# L4PER_PRM register map
Vendor: Texas Instruments
Peripheral module from a debugger description file (folder TDA2Px).
Registers are 32-bit, access per field, reset 0x0 unless marked. A register's access mark holds for its fields unless they carry their own. Offsets are as the file gives them; lines under a group give offsets from that group; [hi:lo] are bit positions; {n}, {i} and the like mark numbered series; 'fields as' and 'values as' point back to an identical list; <NAME> marks a mode.

## L4PER_PRM (part 1 of 2)
0x11C RM_L4PER_GPIO8_CONTEXT reset 0x2 — This register contains dedicated GPIO8 context statuses. [warm reset insensitive]
  [1] LOSTCONTEXT_RFF rw — Specify if RFF-based context has been lost due to a previous power transition or other reset source. (set upon assertion of L4PER_RET_RST signal)
    0=MAINTAINED (Context has been maintained); 1=LOST (Context has been lost)
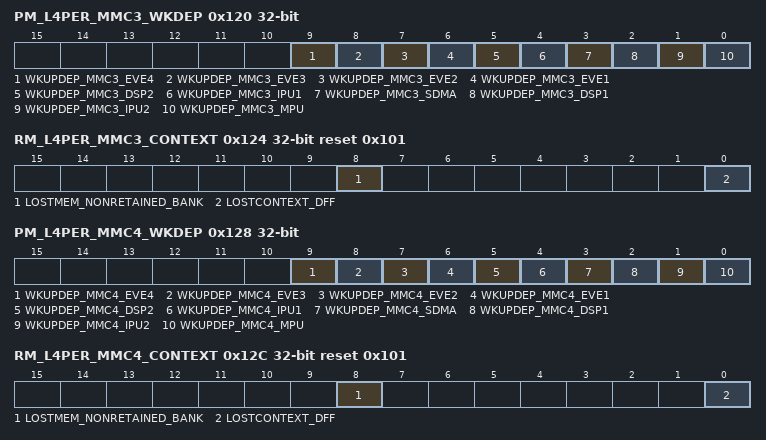
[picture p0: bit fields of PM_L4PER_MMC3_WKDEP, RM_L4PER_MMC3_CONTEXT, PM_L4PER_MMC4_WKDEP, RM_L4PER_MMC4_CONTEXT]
0x120 PM_L4PER_MMC3_WKDEP — This register controls wakeup dependency based on MMC3 service requests.
  [all] fields
    0=DISABLED (Dependency is disabled); 1=ENABLED (Dependency is enabled)
  [9] WKUPDEP_MMC3_EVE4 rw — Wakeup dependency from MMC3 module (SWakeup signal) towards EVE4 + L3_MAIN1 + L4PER1 + L4PER2 + L4PER3 domainsEVE4 is not supported in this family of devices.
  [8] WKUPDEP_MMC3_EVE3 rw — Wakeup dependency from MMC3 module (SWakeup signal) towards EVE3 + L3_MAIN1 + L4PER1 + L4PER2 + L4PER3 domainsEVE3 is not supported in this family of devices.
  [7] WKUPDEP_MMC3_EVE2 rw — Wakeup dependency from MMC3 module (SWakeup signal) towards EVE2 + L3_MAIN1 + L4PER1 + L4PER2 + L4PER3 domains
  [6] WKUPDEP_MMC3_EVE1 rw — Wakeup dependency from MMC3 module (SWakeup signal) towards EVE1 + L3_MAIN1 + L4PER1 + L4PER2 + L4PER3 domains
  [5] WKUPDEP_MMC3_DSP2 rw — Wakeup dependency from MMC3 module (SWakeup signal) towards DSP2 + L3_MAIN1 + L4PER1 + L4PER2 + L4PER3 domains
  [4] WKUPDEP_MMC3_IPU1 rw — Wakeup dependency from MMC3 module (SWakeup signal) towards IPU1 + L3_MAIN1 + L4PER1 + L4PER2 + L4PER3 domains
  [3] WKUPDEP_MMC3_SDMA rw — Wakeup dependency from MMC3 module (SWakeup signal) towards SDMA + L3MAIN1 + L4PER1 + L4PER2 + L4PER3 domains
  [2] WKUPDEP_MMC3_DSP1 rw — Wakeup dependency from MMC3 module (SWakeup signal) towards DSP1 + L3_MAIN1 + L4PER1 + L4PER2 + L4PER3 domains
  [1] WKUPDEP_MMC3_IPU2 rw — Wakeup dependency from MMC3 module (SWakeup signal) towards IPU2 + L3_MAIN1 + L4PER1 + L4PER2 + L4PER3 domains
  [0] WKUPDEP_MMC3_MPU rw — Wakeup dependency from MMC3 module (SWakeup signal) towards MPU + L3_MAIN1 + L4PER1 + L4PER2 + L4PER3 domains
0x124 RM_L4PER_MMC3_CONTEXT reset 0x101 — This register contains dedicated MMC3 context statuses. [warm reset insensitive]
  [8] LOSTMEM_NONRETAINED_BANK rw — Specify if memory-based context in NONRETAINED_BANK memory bank has been lost due to a previous power transition or other reset source.
    values as RM_L4PER_GPIO8_CONTEXT.LOSTCONTEXT_RFF
  [0] LOSTCONTEXT_DFF rw — Specify if DFF-based context has been lost due to a previous power transition or other reset source. (set upon assertion of L4PER_RST signal)
    values as RM_L4PER_GPIO8_CONTEXT.LOSTCONTEXT_RFF
0x128 PM_L4PER_MMC4_WKDEP — This register controls wakeup dependency based on MMC4 service requests.
  [all] fields
    values as the fields of PM_L4PER_MMC3_WKDEP
  [9] WKUPDEP_MMC4_EVE4 rw — Wakeup dependency from MMC4 module (SWakeup signal) towards EVE4 + L3_MAIN1 + L4PER1 + L4PER2 + L4PER3 domainsEVE4 is not supported in this family of devices.
  [8] WKUPDEP_MMC4_EVE3 rw — Wakeup dependency from MMC4 module (SWakeup signal) towards EVE3 + L3_MAIN1 + L4PER1 + L4PER2 + L4PER3 domainsEVE3 is not supported in this family of devices.
  [7] WKUPDEP_MMC4_EVE2 rw — Wakeup dependency from MMC4 module (SWakeup signal) towards EVE2 + L3_MAIN1 + L4PER1 + L4PER2 + L4PER3 domains
  [6] WKUPDEP_MMC4_EVE1 rw — Wakeup dependency from MMC4 module (SWakeup signal) towards EVE1 + L3_MAIN1 + L4PER1 + L4PER2 + L4PER3 domains
  [5] WKUPDEP_MMC4_DSP2 rw — Wakeup dependency from MMC4 module (SWakeup signal) towards DSP2 + L3_MAIN1 + L4PER1 + L4PER2 + L4PER3 domains
  [4] WKUPDEP_MMC4_IPU1 rw — Wakeup dependency from MMC4 module (SWakeup signal) towards IPU1 + L3_MAIN1 + L4PER1 + L4PER2 + L4PER3 domains
  [3] WKUPDEP_MMC4_SDMA rw — Wakeup dependency from MMC4 module (SWakeup signal) towards SDMA + L3MAIN1 + L4PER1 + L4PER2 + L4PER3 domains
  [2] WKUPDEP_MMC4_DSP1 rw — Wakeup dependency from MMC4 module (SWakeup signal) towards DSP1 + L3_MAIN1 + L4PER1 + L4PER2 + L4PER3 domains
  [1] WKUPDEP_MMC4_IPU2 rw — Wakeup dependency from MMC4 module (SWakeup signal) towards IPU2 + L3_MAIN1 + L4PER1 + L4PER2 + L4PER3 domains
  [0] WKUPDEP_MMC4_MPU rw — Wakeup dependency from MMC4 module (SWakeup signal) towards MPU + L3_MAIN1 + L4PER1 + L4PER2 + L4PER3 domains
0x12C RM_L4PER_MMC4_CONTEXT reset 0x101 — This register contains dedicated MMC4 context statuses. [warm reset insensitive]
  fields as RM_L4PER_MMC3_CONTEXT
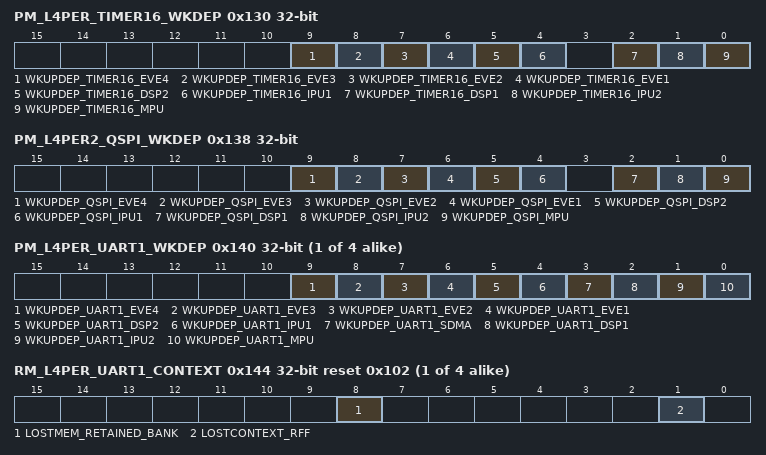
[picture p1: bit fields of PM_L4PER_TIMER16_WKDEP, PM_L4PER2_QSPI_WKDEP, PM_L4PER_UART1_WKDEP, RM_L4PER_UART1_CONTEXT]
0x130 PM_L4PER_TIMER16_WKDEP — This register controls wakeup dependency based on TIMER16 service requests.
  [9] WKUPDEP_TIMER16_EVE4 rw — Wakeup dependency from TIMER16 module (SWakeup IRQ signal) towards EVE4 + L3_MAIN1 + L4PER1 + L4PER2 + L4PER3 domainsEVE4 is not supported in this family of devices.
    values as the fields of PM_L4PER_MMC3_WKDEP
  [8] WKUPDEP_TIMER16_EVE3 rw — Wakeup dependency from TIMER16 module (SWakeup IRQ signal) towards EVE3 + L3_MAIN1 + L4PER1 + L4PER2 + L4PER3 domainsEVE3 is not supported in this family of devices.
    values as the fields of PM_L4PER_MMC3_WKDEP
  [7] WKUPDEP_TIMER16_EVE2 rw — Wakeup dependency from TIMER16 module (SWakeup IRQ signal) towards EVE2 + L3_MAIN1 + L4PER1 + L4PER2 + L4PER3 domains
    values as the fields of PM_L4PER_MMC3_WKDEP
  [6] WKUPDEP_TIMER16_EVE1 rw — Wakeup dependency from TIMER16 module (SWakeup IRQ signal) towards EVE1 + L3_MAIN1 + L4PER1 + L4PER2 + L4PER3 domains
    values as the fields of PM_L4PER_MMC3_WKDEP
  [5] WKUPDEP_TIMER16_DSP2 rw — Wakeup dependency from TIMER16 module (SWakeup IRQ signal) towards DSP2 + L3_MAIN1 + L4PER1 + L4PER2 + L4PER3 domains
    values as the fields of PM_L4PER_MMC3_WKDEP
  [4] WKUPDEP_TIMER16_IPU1 rw — Wakeup dependency from TIMER16 module (SWakeup IRQ signal) towards IPU1 + L3_MAIN1 + L4PER1 + L4PER2 + L4PER3 domains
    values as the fields of PM_L4PER_MMC3_WKDEP
  [2] WKUPDEP_TIMER16_DSP1 rw — Wakeup dependency from TIMER16 module (SWakeup IRQ signal) towards DSP1 + L3_MAIN1 + L4PER1 + L4PER2 + L4PER3 domains
    values as the fields of PM_L4PER_MMC3_WKDEP
  [1] WKUPDEP_TIMER16_IPU2 rw — Wakeup dependency from TIMER16 module (SWakeup IRQ signal) towards IPU2 + L3_MAIN1 + L4PER1 + L4PER2 + L4PER3 domains
    0=Dependency_is_disabled; 1=Dependency_is_enabled
  [0] WKUPDEP_TIMER16_MPU rw — 6Wakeup dependency from TIMER13 module (SWakeup IRQ signal) towards MPU + L3_MAIN1 + L4PER1 + L4PER2 + L4PER3 domains
    values as the fields of PM_L4PER_MMC3_WKDEP
0x134 RM_L4PER3_TIMER16_CONTEXT reset 0x1 — This register contains dedicated TIMER16 context statuses. [warm reset insensitive]
  [0] LOSTCONTEXT_DFF rw — Specify if DFF-based context has been lost due to a previous power transition or other reset source. (set upon assertion of L4PER_RST signal)
    values as RM_L4PER_GPIO8_CONTEXT.LOSTCONTEXT_RFF
0x138 PM_L4PER2_QSPI_WKDEP — This register controls wakeup dependency based on QSPI service requests.
  [9] WKUPDEP_QSPI_EVE4 rw — Wakeup dependency from QSPI module (SWakeup IRQ signal) towards EVE4 + L3_MAIN1 + L4PER1 + L4PER2 + L4PER3 domainsEVE4 is not supported in this family of devices.
    values as the fields of PM_L4PER_MMC3_WKDEP
  [8] WKUPDEP_QSPI_EVE3 rw — Wakeup dependency from QSPI module (SWakeup IRQ signal) towards EVE3 + L3_MAIN1 + L4PER1 + L4PER2 + L4PER3 domainsEVE3 is not supported in this family of devices.
    values as the fields of PM_L4PER_MMC3_WKDEP
  [7] WKUPDEP_QSPI_EVE2 rw — Wakeup dependency from QSPI module (SWakeup IRQ signal) towards EVE2 + L3_MAIN1 + L4PER1 + L4PER2 + L4PER3 domains
    values as the fields of PM_L4PER_MMC3_WKDEP
  [6] WKUPDEP_QSPI_EVE1 rw — Wakeup dependency from QSPI module (SWakeup IRQ signal) towards EVE1 + L3_MAIN1 + L4PER1 + L4PER2 + L4PER3 domains
    values as the fields of PM_L4PER_MMC3_WKDEP
  [5] WKUPDEP_QSPI_DSP2 rw — Wakeup dependency from QSPI module (SWakeup IRQ signal) towards DSP2 + L3_MAIN1 + L4PER1 + L4PER2 + L4PER3 domains
    values as the fields of PM_L4PER_MMC3_WKDEP
  [4] WKUPDEP_QSPI_IPU1 rw — Wakeup dependency from QSPI module (SWakeup IRQ signal) towards IPU1 + L3_MAIN1 + L4PER1 + L4PER2 + L4PER3 domains
    values as the fields of PM_L4PER_MMC3_WKDEP
  [2] WKUPDEP_QSPI_DSP1 rw — Wakeup dependency from QSPI module (SWakeup IRQ signal) towards DSP1 + L3_MAIN1 + L4PER1 + L4PER2 + L4PER3 domains
    values as the fields of PM_L4PER_MMC3_WKDEP
  [1] WKUPDEP_QSPI_IPU2 rw — Wakeup dependency from QSPI module (SWakeup IRQ signal) towards IPU2 + L3_MAIN1 + L4PER1 + L4PER2 + L4PER3 domains
    0=Dependency_is_disabled; 1=Dependency_is_enabled
  [0] WKUPDEP_QSPI_MPU rw — Wakeup dependency from QSPI module (SWakeup IRQ signal) towards MPU + L3_MAIN1 + L4PER1 + L4PER2 + L4PER3 domains
    values as the fields of PM_L4PER_MMC3_WKDEP
0x13C RM_L4PER2_QSPI_CONTEXT reset 0x1 — This register contains dedicated QSPI context statuses. [warm reset insensitive]
  [0] LOSTCONTEXT_DFF rw — Specify if DFF-based context has been lost due to a previous power transition or other reset source. (set upon assertion of CORE_RET_RST signal)
    values as RM_L4PER_GPIO8_CONTEXT.LOSTCONTEXT_RFF
{0x138+8i} PM_L4PER_UART{i}_WKDEP (i=1..4) — This register controls wakeup dependency based on UART{i} service requests.
  [9] WKUPDEP_UART{i}_EVE4 rw — Wakeup dependency from UART{i} module (SWakeup signal) towards EVE4 + L3_MAIN1 + L4PER1 + L4PER2 + L4PER3 domainsEVE4 is not supported in this family of devices.
    values as the fields of PM_L4PER_MMC3_WKDEP
  [8] WKUPDEP_UART{i}_EVE3 rw — Wakeup dependency from UART{i} module (SWakeup signal) towards EVE3 + L3_MAIN1 + L4PER1 + L4PER2 + L4PER3 domainsEVE3 is not supported in this family of devices.
    values as the fields of PM_L4PER_MMC3_WKDEP
  [7] WKUPDEP_UART{i}_EVE2 rw — Wakeup dependency from UART{i} module (SWakeup signal) towards EVE2 + L3_MAIN1 + L4PER1 + L4PER2 + L4PER3 domains
    values as the fields of PM_L4PER_MMC3_WKDEP
  [6] WKUPDEP_UART{i}_EVE1 rw — Wakeup dependency from UART{i} module (SWakeup signal) towards EVE1 + L3_MAIN1 + L4PER1 + L4PER2 + L4PER3 domains
    values as the fields of PM_L4PER_MMC3_WKDEP
  [5] WKUPDEP_UART{i}_DSP2 rw — Wakeup dependency from UART{i} module (SWakeup signal) towards DSP2 + L3_MAIN1 + L4PER1 + L4PER2 + L4PER3 domains
    values as the fields of PM_L4PER_MMC3_WKDEP
  [4] WKUPDEP_UART{i}_IPU1 rw — Wakeup dependency from UART{i} module (SWakeup signal) towards IPU1 + L3_MAIN1 + L4PER1 + L4PER2 + L4PER3 domains
    values as the fields of PM_L4PER_MMC3_WKDEP
  [3] WKUPDEP_UART{i}_SDMA rw — Wakeup dependency from UART{i} module (SWakeup signal) towards SDMA + L3MAIN1 + L4PER1 + L4PER2 + L4PER3 domains
    0=Dependency_is_disabled; 1=Dependency_is_enabled
  [2] WKUPDEP_UART{i}_DSP1 rw — Wakeup dependency from UART{i} module (SWakeup signal) towards DSP1 + L3_MAIN1 + L4PER1 + L4PER2 + L4PER3 domains
    values as the fields of PM_L4PER_MMC3_WKDEP
  [1] WKUPDEP_UART{i}_IPU2 rw — Wakeup dependency from UART{i} module (SWakeup signal) towards IPU2 + L3_MAIN1 + L4PER1 + L4PER2 + L4PER3 domains
    0=Dependency_is_disabled; 1=Dependency_is_enabled
  [0] WKUPDEP_UART{i}_MPU rw — Wakeup dependency from UART{i} module (SWakeup signal) towards MPU + L3_MAIN1 + L4PER1 + L4PER2 + L4PER3 domains
    values as the fields of PM_L4PER_MMC3_WKDEP
{0x13C+8i} RM_L4PER_UART{i}_CONTEXT reset 0x102 (i=1..4) — This register contains dedicated UART{i} context statuses. [warm reset insensitive]
  [8] LOSTMEM_RETAINED_BANK rw — Specify if memory-based context in RETAINED_BANK memory bank has been lost due to a previous power transition or other reset source.
    values as RM_L4PER_GPIO8_CONTEXT.LOSTCONTEXT_RFF
  [1] LOSTCONTEXT_RFF rw — Specify if RFF-based context has been lost due to a previous power transition or other reset source. (set upon assertion of L4PER_RET_RST signal)
    values as RM_L4PER_GPIO8_CONTEXT.LOSTCONTEXT_RFF
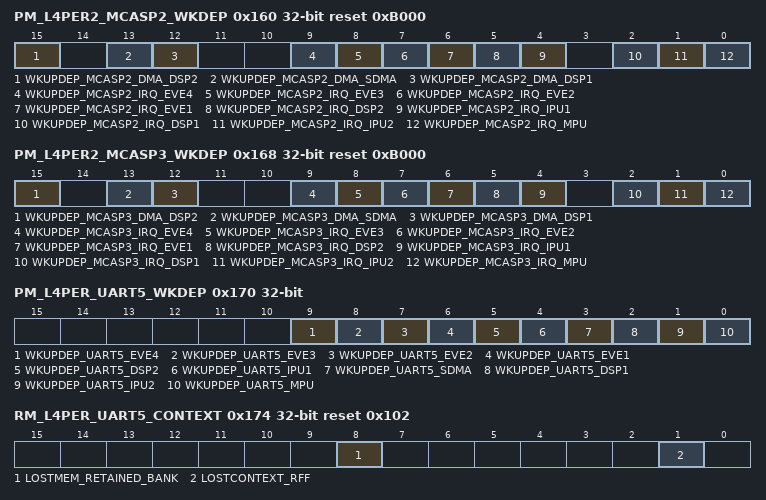
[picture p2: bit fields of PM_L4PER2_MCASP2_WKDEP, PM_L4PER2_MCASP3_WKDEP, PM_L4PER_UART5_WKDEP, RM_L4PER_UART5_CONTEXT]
0x160 PM_L4PER2_MCASP2_WKDEP reset 0xB000 — This register controls wakeup dependency based on MCASP2 service requests.
  [all] fields
    values as the fields of PM_L4PER_MMC3_WKDEP
  [15] WKUPDEP_MCASP2_DMA_DSP2 rw — Wakeup dependency from MCASP2 module (SWakeup_dma signal) towards DSP2 + L3_MAIN1 + L4PER1 + L4PER2 + L4PER3 domains
  [13] WKUPDEP_MCASP2_DMA_SDMA rw — Wakeup dependency from MCASP2 module (SWakeup_dma signal) towards SDMA + L3MAIN1 + L4PER1 + L4PER2 + L4PER3 domains
  [12] WKUPDEP_MCASP2_DMA_DSP1 rw — Wakeup dependency from MCASP2 module (SWakeup_dma signal) towards DSP1 + L3_MAIN1 + L4PER1 + L4PER2 + L4PER3 domains
  [9] WKUPDEP_MCASP2_IRQ_EVE4 rw — Wakeup dependency from MCASP2 module (SWakeup IRQ signal) towards EVE4 + L3_MAIN1 + L4PER1 + L4PER2 + L4PER3 domainsEVE4 is not supported in this family of devices.
  [8] WKUPDEP_MCASP2_IRQ_EVE3 rw — Wakeup dependency from MCASP2 module (SWakeup IRQ signal) towards EVE3 + L3_MAIN1 + L4PER1 + L4PER2 + L4PER3 domainsEVE3 is not supported in this family of devices.
  [7] WKUPDEP_MCASP2_IRQ_EVE2 rw — Wakeup dependency from MCASP2 module (SWakeup IRQ signal) towards EVE2 + L3_MAIN1 + L4PER1 + L4PER2 + L4PER3 domains
  [6] WKUPDEP_MCASP2_IRQ_EVE1 rw — Wakeup dependency from MCASP2 module (SWakeup IRQ signal) towards EVE1 + L3_MAIN1 + L4PER1 + L4PER2 + L4PER3 domains
  [5] WKUPDEP_MCASP2_IRQ_DSP2 rw — Wakeup dependency from MCASP2 module (SWakeup IRQ signal) towards DSP2 + L3_MAIN1 + L4PER1 + L4PER2 + L4PER3 domains
  [4] WKUPDEP_MCASP2_IRQ_IPU1 rw — Wakeup dependency from MCASP2 module (SWakeup IRQ signal) towards IPU1 + L3_MAIN1 + L4PER1 + L4PER2 + L4PER3 domains
  [2] WKUPDEP_MCASP2_IRQ_DSP1 rw — Wakeup dependency from MCASP2 module (SWakeup IRQ signal) towards DSP1 + L3_MAIN1 + L4PER1 + L4PER2 + L4PER3 domains
  [1] WKUPDEP_MCASP2_IRQ_IPU2 rw — Wakeup dependency from MCASP2 module (SWakeup IRQ signal) towards IPU2 + L3_MAIN1 + L4PER1 + L4PER2 + L4PER3 domains
  [0] WKUPDEP_MCASP2_IRQ_MPU rw — Wakeup dependency from MCASP2 module (SWakeup IRQ signal) towards MPU + L3_MAIN1 + L4PER1 + L4PER2 + L4PER3 domains
0x164 RM_L4PER2_MCASP2_CONTEXT reset 0x1 — This register contains dedicated MCASP2 context statuses. [warm reset insensitive]
  fields as RM_L4PER3_TIMER16_CONTEXT
0x168 PM_L4PER2_MCASP3_WKDEP reset 0xB000 — This register controls wakeup dependency based on MCASP3 service requests.
  [all] fields
    values as the fields of PM_L4PER_MMC3_WKDEP
  [15] WKUPDEP_MCASP3_DMA_DSP2 rw — Wakeup dependency from MCASP3 module (SWakeup_dma signal) towards DSP2 + L3_MAIN1 + L4PER1 + L4PER2 + L4PER3 domains
  [13] WKUPDEP_MCASP3_DMA_SDMA rw — Wakeup dependency from MCASP3 module (SWakeup_dma signal) towards SDMA + L3MAIN1 + L4PER1 + L4PER2 + L4PER3 domains
  [12] WKUPDEP_MCASP3_DMA_DSP1 rw — 3Wakeup dependency from MCASP2 module (SWakeup_dma signal) towards DSP1 + L3_MAIN1 + L4PER1 + L4PER2 + L4PER3 domains
  [9] WKUPDEP_MCASP3_IRQ_EVE4 rw — Wakeup dependency from MCASP3 module (SWakeup IRQ signal) towards EVE4 + L3_MAIN1 + L4PER1 + L4PER2 + L4PER3 domainsEVE4 is not supported in this family of devices.
  [8] WKUPDEP_MCASP3_IRQ_EVE3 rw — Wakeup dependency from MCASP3 module (SWakeup IRQ signal) towards EVE3 + L3_MAIN1 + L4PER1 + L4PER2 + L4PER3 domainsEVE3 is not supported in this family of devices.
  [7] WKUPDEP_MCASP3_IRQ_EVE2 rw — Wakeup dependency from MCASP3 module (SWakeup IRQ signal) towards EVE2 + L3_MAIN1 + L4PER1 + L4PER2 + L4PER3 domains
  [6] WKUPDEP_MCASP3_IRQ_EVE1 rw — Wakeup dependency from MCASP3 module (SWakeup IRQ signal) towards EVE1 + L3_MAIN1 + L4PER1 + L4PER2 + L4PER3 domains
  [5] WKUPDEP_MCASP3_IRQ_DSP2 rw — Wakeup dependency from MCASP3 module (SWakeup IRQ signal) towards DSP2 + L3_MAIN1 + L4PER1 + L4PER2 + L4PER3 domains
  [4] WKUPDEP_MCASP3_IRQ_IPU1 rw — Wakeup dependency from MCASP3 module (SWakeup IRQ signal) towards IPU1 + L3_MAIN1 + L4PER1 + L4PER2 + L4PER3 domains
  [2] WKUPDEP_MCASP3_IRQ_DSP1 rw — Wakeup dependency from MCASP3 module (SWakeup IRQ signal) towards DSP1 + L3_MAIN1 + L4PER1 + L4PER2 + L4PER3 domains
  [1] WKUPDEP_MCASP3_IRQ_IPU2 rw — Wakeup dependency from MCASP3 module (SWakeup IRQ signal) towards IPU2 + L3_MAIN1 + L4PER1 + L4PER2 + L4PER3 domains
  [0] WKUPDEP_MCASP3_IRQ_MPU rw — Wakeup dependency from MCASP3 module (SWakeup IRQ signal) towards MPU + L3_MAIN1 + L4PER1 + L4PER2 + L4PER3 domains
0x16C RM_L4PER2_MCASP3_CONTEXT reset 0x1 — This register contains dedicated MCASP3 context statuses. [warm reset insensitive]
  fields as RM_L4PER3_TIMER16_CONTEXT
0x170 PM_L4PER_UART5_WKDEP — This register controls wakeup dependency based on UART5 service requests.
  [9] WKUPDEP_UART5_EVE4 rw — Wakeup dependency from UART5 module (SWakeup signal) towards EVE4 + L3_MAIN1 + L4PER1 + L4PER2 + L4PER3 domainsEVE4 is not supported in this family of devices.
    values as the fields of PM_L4PER_MMC3_WKDEP
  [8] WKUPDEP_UART5_EVE3 rw — Wakeup dependency from UART5 module (SWakeup signal) towards EVE3 + L3_MAIN1 + L4PER1 + L4PER2 + L4PER3 domainsEVE3 is not supported in this family of devices.
    values as the fields of PM_L4PER_MMC3_WKDEP
  [7] WKUPDEP_UART5_EVE2 rw — Wakeup dependency from UART5 module (SWakeup signal) towards EVE2 + L3_MAIN1 + L4PER1 + L4PER2 + L4PER3 domains
    values as the fields of PM_L4PER_MMC3_WKDEP
  [6] WKUPDEP_UART5_EVE1 rw — Wakeup dependency from UART5 module (SWakeup signal) towards EVE1 + L3_MAIN1 + L4PER1 + L4PER2 + L4PER3 domains
    values as the fields of PM_L4PER_MMC3_WKDEP
  [5] WKUPDEP_UART5_DSP2 rw — Wakeup dependency from UART5 module (SWakeup signal) towards DSP2 + L3_MAIN1 + L4PER1 + L4PER2 + L4PER3 domains
    values as the fields of PM_L4PER_MMC3_WKDEP
  [4] WKUPDEP_UART5_IPU1 rw — Wakeup dependency from UART5 module (SWakeup signal) towards IPU1 + L3_MAIN1 + L4PER1 + L4PER2 + L4PER3 domains
    values as the fields of PM_L4PER_MMC3_WKDEP
  [3] WKUPDEP_UART5_SDMA rw — Wakeup dependency from UART5 module (SWakeup signal) towards SDMA + L3MAIN1 + L4PER1 + L4PER2 + L4PER3 domains
    0=Dependency_is_disabled; 1=Dependency_is_enabled
  [2] WKUPDEP_UART5_DSP1 rw — Wakeup dependency from UART5 module (SWakeup signal) towards DSP1 + L3_MAIN1 + L4PER1 + L4PER2 + L4PER3 domains
    values as the fields of PM_L4PER_MMC3_WKDEP
  [1] WKUPDEP_UART5_IPU2 rw — Wakeup dependency from UART5 module (SWakeup signal) towards IPU2 + L3_MAIN1 + L4PER1 + L4PER2 + L4PER3 domains
    0=Dependency_is_disabled; 1=Dependency_is_enabled
  [0] WKUPDEP_UART5_MPU rw — Wakeup dependency from UART5 module (SWakeup signal) towards MPU + L3_MAIN1 + L4PER1 + L4PER2 + L4PER3 domains
    values as the fields of PM_L4PER_MMC3_WKDEP
0x174 RM_L4PER_UART5_CONTEXT reset 0x102 — This register contains dedicated UART5 context statuses. [warm reset insensitive]
  fields as RM_L4PER_UART1_CONTEXT
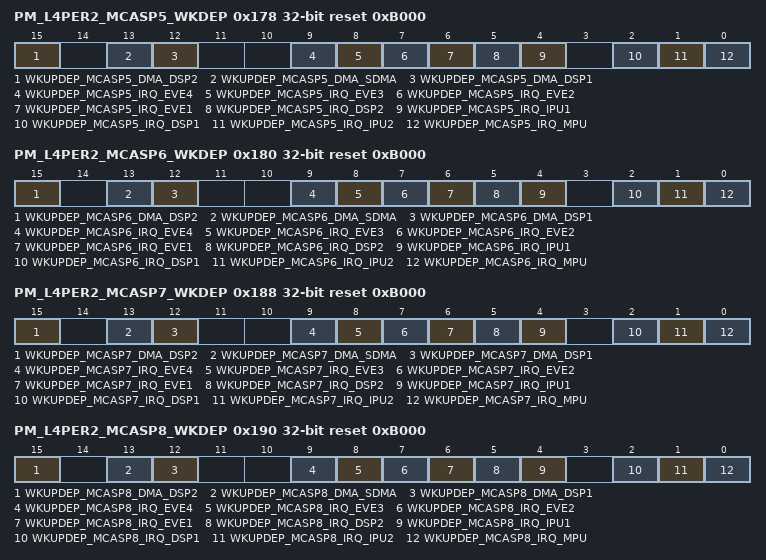
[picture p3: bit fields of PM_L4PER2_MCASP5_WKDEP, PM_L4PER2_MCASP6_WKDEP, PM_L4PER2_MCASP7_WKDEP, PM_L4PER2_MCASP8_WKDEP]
0x178 PM_L4PER2_MCASP5_WKDEP reset 0xB000 — This register controls wakeup dependency based on MCASP5 service requests.
  [all] fields
    values as the fields of PM_L4PER_MMC3_WKDEP
  [15] WKUPDEP_MCASP5_DMA_DSP2 rw — Wakeup dependency from MCASP5 module (SWakeup_dma signal) towards DSP2 + L3_MAIN1 + L4PER1 + L4PER2 + L4PER3 domains
  [13] WKUPDEP_MCASP5_DMA_SDMA rw — Wakeup dependency from MCASP5 module (SWakeup_dma signal) towards SDMA + L3MAIN1 + L4PER1 + L4PER2 + L4PER3 domains
  [12] WKUPDEP_MCASP5_DMA_DSP1 rw — Wakeup dependency from MCASP5 module (SWakeup_dma signal) towards DSP1 + L3_MAIN1 + L4PER1 + L4PER2 + L4PER3 domains
  [9] WKUPDEP_MCASP5_IRQ_EVE4 rw — Wakeup dependency from MCASP5 module (SWakeup IRQ signal) towards EVE4 + L3_MAIN1 + L4PER1 + L4PER2 + L4PER3 domainsEVE4 is not supported in this family of devices.
  [8] WKUPDEP_MCASP5_IRQ_EVE3 rw — Wakeup dependency from MCASP5 module (SWakeup IRQ signal) towards EVE3 + L3_MAIN1 + L4PER1 + L4PER2 + L4PER3 domainsEVE3 is not supported in this family of devices.
  [7] WKUPDEP_MCASP5_IRQ_EVE2 rw — Wakeup dependency from MCASP5 module (SWakeup IRQ signal) towards EVE2 + L3_MAIN1 + L4PER1 + L4PER2 + L4PER3 domains
  [6] WKUPDEP_MCASP5_IRQ_EVE1 rw — Wakeup dependency from MCASP5 module (SWakeup IRQ signal) towards EVE1 + L3_MAIN1 + L4PER1 + L4PER2 + L4PER3 domains
  [5] WKUPDEP_MCASP5_IRQ_DSP2 rw — Wakeup dependency from MCASP5 module (SWakeup IRQ signal) towards DSP2 + L3_MAIN1 + L4PER1 + L4PER2 + L4PER3 domains
  [4] WKUPDEP_MCASP5_IRQ_IPU1 rw — Wakeup dependency from MCASP5 module (SWakeup IRQ signal) towards IPU1 + L3_MAIN1 + L4PER1 + L4PER2 + L4PER3 domains
  [2] WKUPDEP_MCASP5_IRQ_DSP1 rw — Wakeup dependency from MCASP5 module (SWakeup IRQ signal) towards DSP1 + L3_MAIN1 + L4PER1 + L4PER2 + L4PER3 domains
  [1] WKUPDEP_MCASP5_IRQ_IPU2 rw — Wakeup dependency from MCASP2 module (SWakeup IRQ signal) towards IPU2 + L3_MAIN1 + L4PER1 + L4PER2 + L4PER3 domains
  [0] WKUPDEP_MCASP5_IRQ_MPU rw — Wakeup dependency from MCASP5 module (SWakeup IRQ signal) towards MPU + L3_MAIN1 + L4PER1 + L4PER2 + L4PER3 domains
{0x154+8i} RM_L4PER2_MCASP{i}_CONTEXT reset 0x1 (i=5..7) — This register contains dedicated MCASP{i} context statuses. [warm reset insensitive]
  fields as RM_L4PER3_TIMER16_CONTEXT
0x180 PM_L4PER2_MCASP6_WKDEP reset 0xB000 — This register controls wakeup dependency based on MCASP6 service requests.
  [all] fields
    values as the fields of PM_L4PER_MMC3_WKDEP
  [15] WKUPDEP_MCASP6_DMA_DSP2 rw — Wakeup dependency from MCASP6 module (SWakeup_dma signal) towards DSP2 + L3_MAIN1 + L4PER1 + L4PER2 + L4PER3 domains
  [13] WKUPDEP_MCASP6_DMA_SDMA rw — Wakeup dependency from MCASP6 module (SWakeup_dma signal) towards SDMA + L3MAIN1 + L4PER1 + L4PER2 + L4PER3 domains
  [12] WKUPDEP_MCASP6_DMA_DSP1 rw — Wakeup dependency from MCASP6 module (SWakeup_dma signal) towards DSP1 + L3_MAIN1 + L4PER1 + L4PER2 + L4PER3 domains
  [9] WKUPDEP_MCASP6_IRQ_EVE4 rw — Wakeup dependency from MCASP6 module (SWakeup IRQ signal) towards EVE4 + L3_MAIN1 + L4PER1 + L4PER2 + L4PER3 domainsEVE4 is not supported in this family of devices.
  [8] WKUPDEP_MCASP6_IRQ_EVE3 rw — Wakeup dependency from MCASP6 module (SWakeup IRQ signal) towards EVE3 + L3_MAIN1 + L4PER1 + L4PER2 + L4PER3 domainsEVE3 is not supported in this family of devices.
  [7] WKUPDEP_MCASP6_IRQ_EVE2 rw — Wakeup dependency from MCASP6 module (SWakeup IRQ signal) towards EVE2 + L3_MAIN1 + L4PER1 + L4PER2 + L4PER3 domains
  [6] WKUPDEP_MCASP6_IRQ_EVE1 rw — Wakeup dependency from MCASP6 module (SWakeup IRQ signal) towards EVE1 + L3_MAIN1 + L4PER1 + L4PER2 + L4PER3 domains
  [5] WKUPDEP_MCASP6_IRQ_DSP2 rw — Wakeup dependency from MCASP6 module (SWakeup IRQ signal) towards DSP2 + L3_MAIN1 + L4PER1 + L4PER2 + L4PER3 domains
  [4] WKUPDEP_MCASP6_IRQ_IPU1 rw — Wakeup dependency from MCASP6 module (SWakeup IRQ signal) towards IPU1 + L3_MAIN1 + L4PER1 + L4PER2 + L4PER3 domains
  [2] WKUPDEP_MCASP6_IRQ_DSP1 rw — Wakeup dependency from MCASP6 module (SWakeup IRQ signal) towards DSP1 + L3_MAIN1 + L4PER1 + L4PER2 + L4PER3 domains
  [1] WKUPDEP_MCASP6_IRQ_IPU2 rw — Wakeup dependency from MCASP6 (SWakeup IRQ signal) towards IPU2 + L3_MAIN1 + L4PER1 + L4PER2 + L4PER3 domains
  [0] WKUPDEP_MCASP6_IRQ_MPU rw — Wakeup dependency from MCASP6 module (SWakeup IRQ signal) towards MPU + L3_MAIN1 + L4PER1 + L4PER2 + L4PER3 domains
0x188 PM_L4PER2_MCASP7_WKDEP reset 0xB000 — This register controls wakeup dependency based on MCASP7 service requests.
  [all] fields
    values as the fields of PM_L4PER_MMC3_WKDEP
  [15] WKUPDEP_MCASP7_DMA_DSP2 rw — Wakeup dependency from MCASP7 module (SWakeup_dma signal) towards DSP2 + L3_MAIN1 + L4PER1 + L4PER2 + L4PER3 domains
  [13] WKUPDEP_MCASP7_DMA_SDMA rw — Wakeup dependency from MCASP7 module (SWakeup_dma signal) towards SDMA + L3MAIN1 + L4PER1 + L4PER2 + L4PER3 domains
  [12] WKUPDEP_MCASP7_DMA_DSP1 rw — Wakeup dependency from MCASP7 module (SWakeup_dma signal) towards DSP1 + L3_MAIN1 + L4PER1 + L4PER2 + L4PER3 domains
  [9] WKUPDEP_MCASP7_IRQ_EVE4 rw — Wakeup dependency from MCASP7 module (SWakeup IRQ signal) towards EVE4 + L3_MAIN1 + L4PER1 + L4PER2 + L4PER3 domainsEVE4 is not supported in this family of devices.
  [8] WKUPDEP_MCASP7_IRQ_EVE3 rw — Wakeup dependency from MCASP7 module (SWakeup IRQ signal) towards EVE3 + L3_MAIN1 + L4PER1 + L4PER2 + L4PER3 domainsEVE3 is not supported in this family of devices.
  [7] WKUPDEP_MCASP7_IRQ_EVE2 rw — Wakeup dependency from MCASP7 module (SWakeup IRQ signal) towards EVE2 + L3_MAIN1 + L4PER1 + L4PER2 + L4PER3 domains
  [6] WKUPDEP_MCASP7_IRQ_EVE1 rw — Wakeup dependency from MCASP7 module (SWakeup IRQ signal) towards EVE1 + L3_MAIN1 + L4PER1 + L4PER2 + L4PER3 domains
  [5] WKUPDEP_MCASP7_IRQ_DSP2 rw — Wakeup dependency from MCASP7 module (SWakeup IRQ signal) towards DSP2 + L3_MAIN1 + L4PER1 + L4PER2 + L4PER3 domains
  [4] WKUPDEP_MCASP7_IRQ_IPU1 rw — Wakeup dependency from MCASP7 module (SWakeup IRQ signal) towards IPU1 + L3_MAIN1 + L4PER1 + L4PER2 + L4PER3 domains
  [2] WKUPDEP_MCASP7_IRQ_DSP1 rw — Wakeup dependency from MCASP7 module (SWakeup IRQ signal) towards DSP1 + L3_MAIN1 + L4PER1 + L4PER2 + L4PER3 domains
  [1] WKUPDEP_MCASP7_IRQ_IPU2 rw — Wakeup dependency from MCASP7 module (SWakeup IRQ signal) towards IPU2 + L3_MAIN1 + L4PER1 + L4PER2 + L4PER3 domains
  [0] WKUPDEP_MCASP7_IRQ_MPU rw — Wakeup dependency from MCASP7 module (SWakeup IRQ signal) towards MPU + L3_MAIN1 + L4PER1 + L4PER2 + L4PER3 domains
0x190 PM_L4PER2_MCASP8_WKDEP reset 0xB000 — This register controls wakeup dependency based on MCASP8 service requests.
  [all] fields
    values as the fields of PM_L4PER_MMC3_WKDEP
  [15] WKUPDEP_MCASP8_DMA_DSP2 rw — Wakeup dependency from MCASP8 module (SWakeup_dma signal) towards DSP2 + L3_MAIN1 + L4PER1 + L4PER2 + L4PER3 domains
  [13] WKUPDEP_MCASP8_DMA_SDMA rw — Wakeup dependency from MCASP8 module (SWakeup_dma signal) towards SDMA + L3MAIN1 + L4PER1 + L4PER2 + L4PER3 domains
  [12] WKUPDEP_MCASP8_DMA_DSP1 rw — Wakeup dependency from MCASP8 module (SWakeup_dma signal) towards DSP1 + L3_MAIN1 + L4PER1 + L4PER2 + L4PER3 domains
  [9] WKUPDEP_MCASP8_IRQ_EVE4 rw — Wakeup dependency from MCASP8 module (SWakeup IRQ signal) towards EVE4 + L3_MAIN1 + L4PER1 + L4PER2 + L4PER3 domainsEVE4 is not supported in this family of devices.
  [8] WKUPDEP_MCASP8_IRQ_EVE3 rw — Wakeup dependency from MCASP8 module (SWakeup IRQ signal) towards EVE3 + L3_MAIN1 + L4PER1 + L4PER2 + L4PER3 domainsEVE3 is not supported in this family of devices.
  [7] WKUPDEP_MCASP8_IRQ_EVE2 rw — Wakeup dependency from MCASP8 module (SWakeup IRQ signal) towards EVE2 + L3_MAIN1 + L4PER1 + L4PER2 + L4PER3 domains
  [6] WKUPDEP_MCASP8_IRQ_EVE1 rw — Wakeup dependency from MCASP8 module (SWakeup IRQ signal) towards EVE1 + L3_MAIN1 + L4PER1 + L4PER2 + L4PER3 domains
  [5] WKUPDEP_MCASP8_IRQ_DSP2 rw — Wakeup dependency from MCASP8 module (SWakeup IRQ signal) towards DSP2 + L3_MAIN1 + L4PER1 + L4PER2 + L4PER3 domains
  [4] WKUPDEP_MCASP8_IRQ_IPU1 rw — Wakeup dependency from MCASP8 module (SWakeup IRQ signal) towards IPU1 + L3_MAIN1 + L4PER1 + L4PER2 + L4PER3 domains
  [2] WKUPDEP_MCASP8_IRQ_DSP1 rw — Wakeup dependency from MCASP8 module (SWakeup IRQ signal) towards DSP1 + L3_MAIN1 + L4PER1 + L4PER2 + L4PER3 domains
  [1] WKUPDEP_MCASP8_IRQ_IPU2 rw — Wakeup dependency from MCASP8 module (SWakeup IRQ signal) towards IPU2 + L3_MAIN1 + L4PER1 + L4PER2 + L4PER3 domains
  [0] WKUPDEP_MCASP8_IRQ_MPU rw — Wakeup dependency from MCASP8 module (SWakeup IRQ signal) towards MPU + L3_MAIN1 + L4PER1 + L4PER2 + L4PER3 domains
0x194 RM_L4PER2_MCASP8_CONTEXT reset 0x1 — This register contains dedicated MCASP8 context statuses. [warm reset insensitive]
  [0] LOSTCONTEXT_DFF rw — Specify if DFF-based context has been lost due to a previous power transition or other reset source. (set upon assertion of ABE_RST signal)
    values as RM_L4PER_GPIO8_CONTEXT.LOSTCONTEXT_RFF
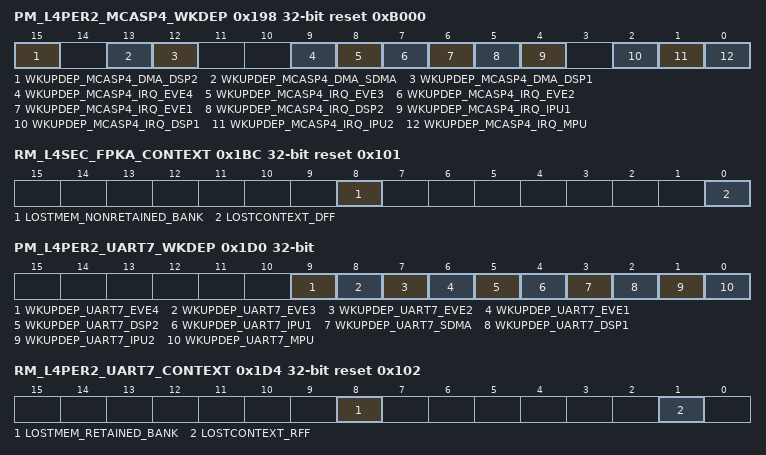
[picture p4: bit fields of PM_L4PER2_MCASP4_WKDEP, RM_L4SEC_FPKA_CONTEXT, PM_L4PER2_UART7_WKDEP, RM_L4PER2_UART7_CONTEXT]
0x198 PM_L4PER2_MCASP4_WKDEP reset 0xB000 — This register controls wakeup dependency based on MCASP4 service requests.
  [all] fields
    values as the fields of PM_L4PER_MMC3_WKDEP
  [15] WKUPDEP_MCASP4_DMA_DSP2 rw — Wakeup dependency from MCASP4 module (SWakeup_dma signal) towards DSP2 + L3_MAIN1 + L4PER1 + L4PER2 + L4PER3 domains
  [13] WKUPDEP_MCASP4_DMA_SDMA rw — Wakeup dependency from MCASP4 module (SWakeup_dma signal) towards SDMA + L3MAIN1 + L4PER1 + L4PER2 + L4PER3 domains
  [12] WKUPDEP_MCASP4_DMA_DSP1 rw — Wakeup dependency from MCASP4 module (SWakeup_dma signal) towards DSP1 + L3_MAIN1 + L4PER1 + L4PER2 + L4PER3 domains
  [9] WKUPDEP_MCASP4_IRQ_EVE4 rw — Wakeup dependency from MCASP4 module (SWakeup IRQ signal) towards EVE4 + L3_MAIN1 + L4PER1 + L4PER2 + L4PER3 domainsEVE4 is not supported in this family of devices.
  [8] WKUPDEP_MCASP4_IRQ_EVE3 rw — Wakeup dependency from MCASP4 module (SWakeup IRQ signal) towards EVE3 + L3_MAIN1 + L4PER1 + L4PER2 + L4PER3 domainsEVE3 is not supported in this family of devices.
  [7] WKUPDEP_MCASP4_IRQ_EVE2 rw — Wakeup dependency from MCASP4 module (SWakeup IRQ signal) towards EVE2 + L3_MAIN1 + L4PER1 + L4PER2 + L4PER3 domains
  [6] WKUPDEP_MCASP4_IRQ_EVE1 rw — Wakeup dependency from MCASP4 module (SWakeup IRQ signal) towards EVE1 + L3_MAIN1 + L4PER1 + L4PER2 + L4PER3 domains
  [5] WKUPDEP_MCASP4_IRQ_DSP2 rw — Wakeup dependency from MCASP4 module (SWakeup IRQ signal) towards DSP2 + L3_MAIN1 + L4PER1 + L4PER2 + L4PER3 domains
  [4] WKUPDEP_MCASP4_IRQ_IPU1 rw — Wakeup dependency from MCASP4 module (SWakeup IRQ signal) towards IPU1 + L3_MAIN1 + L4PER1 + L4PER2 + L4PER3 domains
  [2] WKUPDEP_MCASP4_IRQ_DSP1 rw — Wakeup dependency from MCASP4 module (SWakeup IRQ signal) towards DSP1 + L3_MAIN1 + L4PER1 + L4PER2 + L4PER3 domains
  [1] WKUPDEP_MCASP4_IRQ_IPU2 rw — Wakeup dependency from MCASP4 module (SWakeup IRQ signal) towards IPU2 + L3_MAIN1 + L4PER1 + L4PER2 + L4PER3 domains
  [0] WKUPDEP_MCASP4_IRQ_MPU rw — Wakeup dependency from MCASP4 module (SWakeup IRQ signal) towards MPU + L3_MAIN1 + L4PER1 + L4PER2 + L4PER3 domains
0x19C RM_L4PER2_MCASP4_CONTEXT reset 0x1 — This register contains dedicated MCASP4 context statuses. [warm reset insensitive]
  fields as RM_L4PER3_TIMER16_CONTEXT
0x1A4 RM_L4SEC_AES1_CONTEXT reset 0x2 — This register contains dedicated AES1 context statuses. [warm reset insensitive]
  fields as RM_L4PER_GPIO8_CONTEXT
0x1AC RM_L4SEC_AES2_CONTEXT reset 0x2 — This register contains dedicated AES2 context statuses. [warm reset insensitive]
  fields as RM_L4PER_GPIO8_CONTEXT
0x1B4 RM_L4SEC_DES3DES_CONTEXT reset 0x2 — This register contains dedicated DES3DES context statuses. [warm reset insensitive]
  fields as RM_L4PER_GPIO8_CONTEXT
0x1BC RM_L4SEC_FPKA_CONTEXT reset 0x101 — This register contains dedicated FPKA context statuses. [warm reset insensitive]
  fields as RM_L4PER_MMC3_CONTEXT
0x1C4 RM_L4SEC_RNG_CONTEXT reset 0x2 — This register contains dedicated RNG context statuses. [warm reset insensitive]
  fields as RM_L4PER_GPIO8_CONTEXT
0x1CC RM_L4SEC_SHA2MD51_CONTEXT reset 0x2 — This register contains dedicated SHA2MD51 context statuses. [warm reset insensitive]
  fields as RM_L4PER_GPIO8_CONTEXT
0x1D0 PM_L4PER2_UART7_WKDEP — This register controls wakeup dependency based on UART7 service requests.
  [9] WKUPDEP_UART7_EVE4 rw — Wakeup dependency from UART7 module (SWakeup signal) towards EVE4 + L3_MAIN1 + L4PER1 + L4PER2 + L4PER3 domainsEVE4 is not supported in this family of devices.
    values as the fields of PM_L4PER_MMC3_WKDEP
  [8] WKUPDEP_UART7_EVE3 rw — Wakeup dependency from UART7 module (SWakeup signal) towards EVE3 + L3_MAIN1 + L4PER1 + L4PER2 + L4PER3 domainsEVE3 is not supported in this family of devices.
    values as the fields of PM_L4PER_MMC3_WKDEP
  [7] WKUPDEP_UART7_EVE2 rw — Wakeup dependency from UART7 module (SWakeup signal) towards EVE2 + L3_MAIN1 + L4PER1 + L4PER2 + L4PER3 domains
    values as the fields of PM_L4PER_MMC3_WKDEP
  [6] WKUPDEP_UART7_EVE1 rw — Wakeup dependency from UART7 module (SWakeup signal) towards EVE1 + L3_MAIN1 + L4PER1 + L4PER2 + L4PER3 domains
    values as the fields of PM_L4PER_MMC3_WKDEP
  [5] WKUPDEP_UART7_DSP2 rw — Wakeup dependency from UART7 module (SWakeup signal) towards DSP2 + L3_MAIN1 + L4PER1 + L4PER2 + L4PER3 domains
    values as the fields of PM_L4PER_MMC3_WKDEP
  [4] WKUPDEP_UART7_IPU1 rw — Wakeup dependency from UART7 module (SWakeup signal) towards IPU1 + L3_MAIN1 + L4PER1 + L4PER2 + L4PER3 domains
    values as the fields of PM_L4PER_MMC3_WKDEP
  [3] WKUPDEP_UART7_SDMA rw — Wakeup dependency from UART7 module (SWakeup signal) towards SDMA + L3MAIN1 + L4PER1 + L4PER2 + L4PER3 domains
    0=Dependency_is_disabled; 1=Dependency_is_enabled
  [2] WKUPDEP_UART7_DSP1 rw — Wakeup dependency from UART7 module (SWakeup signal) towards DSP1 + L3_MAIN1 + L4PER1 + L4PER2 + L4PER3 domains
    values as the fields of PM_L4PER_MMC3_WKDEP
  [1] WKUPDEP_UART7_IPU2 rw — Wakeup dependency from UART7 module (SWakeup signal) towards IPU2 + L3_MAIN1 + L4PER1 + L4PER2 + L4PER3 domains
    0=Dependency_is_disabled; 1=Dependency_is_enabled
  [0] WKUPDEP_UART7_MPU rw — Wakeup dependency from UART7 module (SWakeup signal) towards MPU + L3_MAIN1 + L4PER1 + L4PER2 + L4PER3 domains
    values as the fields of PM_L4PER_MMC3_WKDEP
0x1D4 RM_L4PER2_UART7_CONTEXT reset 0x102 — This register contains dedicated UART7 context statuses. [warm reset insensitive]
  fields as RM_L4PER_UART1_CONTEXT
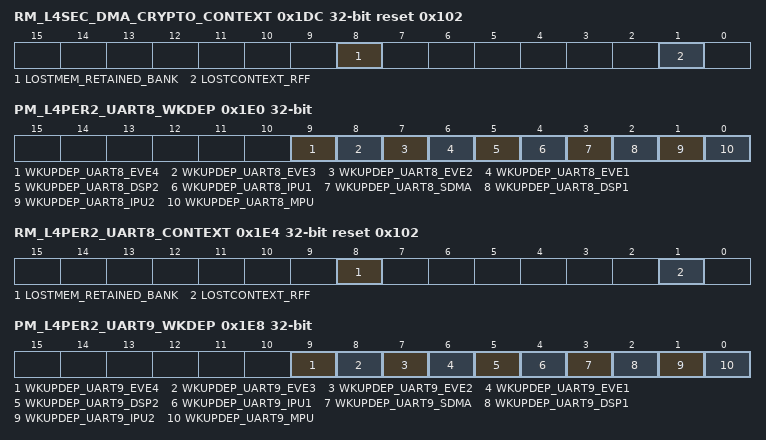
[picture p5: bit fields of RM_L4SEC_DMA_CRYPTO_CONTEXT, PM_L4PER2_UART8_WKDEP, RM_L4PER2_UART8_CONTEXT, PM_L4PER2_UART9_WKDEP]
0x1DC RM_L4SEC_DMA_CRYPTO_CONTEXT reset 0x102 — This register contains dedicated DMA_CRYPTO context statuses. [warm reset insensitive]
  fields as RM_L4PER_UART1_CONTEXT
0x1E0 PM_L4PER2_UART8_WKDEP — This register controls wakeup dependency based on UART8 service requests.
  [9] WKUPDEP_UART8_EVE4 rw — Wakeup dependency from UART8 module (SWakeup signal) towards EVE4 + L3_MAIN1 + L4PER1 + L4PER2 + L4PER3 domainsEVE4 is not supported in this family of devices.
    values as the fields of PM_L4PER_MMC3_WKDEP
  [8] WKUPDEP_UART8_EVE3 rw — Wakeup dependency from UART8 module (SWakeup signal) towards EVE3 + L3_MAIN1 + L4PER1 + L4PER2 + L4PER3 domainsEVE3 is not supported in this family of devices.
    values as the fields of PM_L4PER_MMC3_WKDEP
  [7] WKUPDEP_UART8_EVE2 rw — Wakeup dependency from UART8 module (SWakeup signal) towards EVE2 + L3_MAIN1 + L4PER1 + L4PER2 + L4PER3 domains
    values as the fields of PM_L4PER_MMC3_WKDEP
  [6] WKUPDEP_UART8_EVE1 rw — Wakeup dependency from UART8 module (SWakeup signal) towards EVE1 + L3_MAIN1 + L4PER1 + L4PER2 + L4PER3 domains
    values as the fields of PM_L4PER_MMC3_WKDEP
  [5] WKUPDEP_UART8_DSP2 rw — Wakeup dependency from UART8 module (SWakeup signal) towards DSP2 + L3_MAIN1 + L4PER1 + L4PER2 + L4PER3 domains
    values as the fields of PM_L4PER_MMC3_WKDEP
  [4] WKUPDEP_UART8_IPU1 rw — Wakeup dependency from UART8 module (SWakeup signal) towards IPU1 + L3_MAIN1 + L4PER1 + L4PER2 + L4PER3 domains
    values as the fields of PM_L4PER_MMC3_WKDEP
  [3] WKUPDEP_UART8_SDMA rw — Wakeup dependency from UART8 module (SWakeup signal) towards SDMA + L3_MAIN1 + L4PER1 + L4PER2 + L4PER3 domains
    0=Dependency_is_disabled; 1=Dependency_is_enabled
  [2] WKUPDEP_UART8_DSP1 rw — Wakeup dependency from UART8 module (SWakeup signal) towards DSP1 + L3_MAIN1 + L4PER1 + L4PER2 + L4PER3 domains
    values as the fields of PM_L4PER_MMC3_WKDEP
  [1] WKUPDEP_UART8_IPU2 rw — Wakeup dependency from UART8 module (SWakeup signal) towards IPU2 + L3_MAIN1 + L4PER1 + L4PER2 + L4PER3 domains
    0=Dependency_is_disabled; 1=Dependency_is_enabled
  [0] WKUPDEP_UART8_MPU rw — Wakeup dependency from UART8 module (SWakeup signal) towards MPU + L3_MAIN1 + L4PER1 + L4PER2 + L4PER3 domains
    values as the fields of PM_L4PER_MMC3_WKDEP
0x1E4 RM_L4PER2_UART8_CONTEXT reset 0x102 — This register contains dedicated UART8 context statuses. [warm reset insensitive]
  fields as RM_L4PER_UART1_CONTEXT
0x1E8 PM_L4PER2_UART9_WKDEP — This register controls wakeup dependency based on UART9 service requests.
  [9] WKUPDEP_UART9_EVE4 rw — Wakeup dependency from UART9 module (SWakeup signal) towards EVE4 + L3_MAIN1 + L4PER1 + L4PER2 + L4PER3 domainsEVE4 is not supported in this family of devices.
    values as the fields of PM_L4PER_MMC3_WKDEP
  [8] WKUPDEP_UART9_EVE3 rw — Wakeup dependency from UART9 module (SWakeup signal) towards EVE3 + L3_MAIN1 + L4PER1 + L4PER2 + L4PER3 domainsEVE3 is not supported in this family of devices.
    values as the fields of PM_L4PER_MMC3_WKDEP
  [7] WKUPDEP_UART9_EVE2 rw — Wakeup dependency from UART9 module (SWakeup signal) towards EVE2 + L3_MAIN1 + L4PER1 + L4PER2 + L4PER3 domains
    values as the fields of PM_L4PER_MMC3_WKDEP
  [6] WKUPDEP_UART9_EVE1 rw — Wakeup dependency from UART9 module (SWakeup signal) towards EVE1 + L3_MAIN1 + L4PER1 + L4PER2 + L4PER3 domains
    values as the fields of PM_L4PER_MMC3_WKDEP
  [5] WKUPDEP_UART9_DSP2 rw — Wakeup dependency from UART9 module (SWakeup signal) towards DSP2 + L3_MAIN1 + L4PER1 + L4PER2 + L4PER3 domains
    values as the fields of PM_L4PER_MMC3_WKDEP
  [4] WKUPDEP_UART9_IPU1 rw — Wakeup dependency from UART9 module (SWakeup signal) towards IPU1 + L3_MAIN1 + L4PER1 + L4PER2 + L4PER3 domains
    values as the fields of PM_L4PER_MMC3_WKDEP
  [3] WKUPDEP_UART9_SDMA rw — Wakeup dependency from UART9 module (SWakeup signal) towards SDMA + L3_MAIN1 + L4PER1 + L4PER2 + L4PER3 domains
    0=Dependency_is_disabled; 1=Dependency_is_enabled
  [2] WKUPDEP_UART9_DSP1 rw — Wakeup dependency from UART4 module (SWakeup signal) towards DSP1 + L3_MAIN1 + L4PER1 + L4PER2 + L4PER3 domains
    values as the fields of PM_L4PER_MMC3_WKDEP
  [1] WKUPDEP_UART9_IPU2 rw — Wakeup dependency from UART9 module (SWakeup signal) towards IPU2 + L3_MAIN1 + L4PER1 + L4PER2 + L4PER3 domains
    0=Dependency_is_disabled; 1=Dependency_is_enabled
  [0] WKUPDEP_UART9_MPU rw — Wakeup dependency from UART9 module (SWakeup signal) towards MPU + L3_MAIN1 + L4PER1 + L4PER2 + L4PER3 domains
    values as the fields of PM_L4PER_MMC3_WKDEP
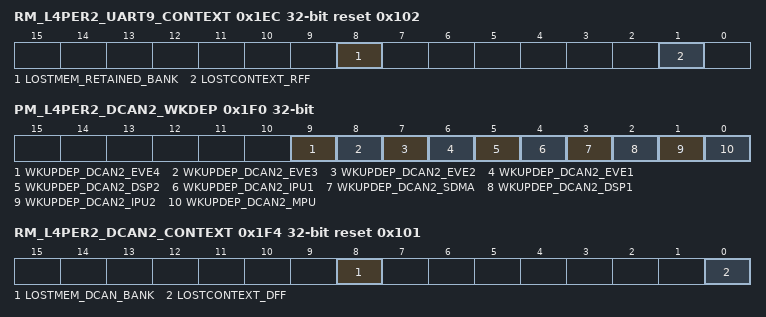
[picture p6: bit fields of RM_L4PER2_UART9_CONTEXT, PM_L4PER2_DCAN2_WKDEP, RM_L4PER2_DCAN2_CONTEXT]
0x1EC RM_L4PER2_UART9_CONTEXT reset 0x102 — This register contains dedicated UART9 context statuses. [warm reset insensitive]
  fields as RM_L4PER_UART1_CONTEXT
0x1F0 PM_L4PER2_DCAN2_WKDEP — This register controls wakeup dependency based on DCAN2 service requests.
  [9] WKUPDEP_DCAN2_EVE4 rw — Wakeup dependency from DCAN2 module (SWakeup signal) towards EVE4 + L3_MAIN1 + L4PER1 + L4PER2 + L4PER3 domainsEVE4 is not supported in this family of devices.
    values as the fields of PM_L4PER_MMC3_WKDEP
  [8] WKUPDEP_DCAN2_EVE3 rw — Wakeup dependency from DCAN2 module (SWakeup signal) towards EVE3 + L3_MAIN1 + L4PER1 + L4PER2 + L4PER3 domainsEVE3 is not supported in this family of devices.
    values as the fields of PM_L4PER_MMC3_WKDEP
  [7] WKUPDEP_DCAN2_EVE2 rw — Wakeup dependency from DCAN2 module (SWakeup signal) towards EVE2 + L3_MAIN1 + L4PER1 + L4PER2 + L4PER3 domains
    values as the fields of PM_L4PER_MMC3_WKDEP
  [6] WKUPDEP_DCAN2_EVE1 rw — Wakeup dependency from DCAN2 module (SWakeup signal) towards EVE1 + L3_MAIN1 + L4PER1 + L4PER2 + L4PER3 domains
    values as the fields of PM_L4PER_MMC3_WKDEP
  [5] WKUPDEP_DCAN2_DSP2 rw — Wakeup dependency from DCAN2 module (SWakeup signal) towards DSP2 + L3_MAIN1 + L4PER1 + L4PER2 + L4PER3 domains
    values as the fields of PM_L4PER_MMC3_WKDEP
  [4] WKUPDEP_DCAN2_IPU1 rw — Wakeup dependency from DCAN2 module (SWakeup signal) towards IPU1 + L3_MAIN1 + L4PER1 + L4PER2 + L4PER3 domains
    values as the fields of PM_L4PER_MMC3_WKDEP
  [3] WKUPDEP_DCAN2_SDMA rw — Wakeup dependency from DCAN2 module (SWakeup signal) towards SDMA + L3MAIN1 + L4PER1 + L4PER2 + L4PER3 domains
    0=Dependency_is_disabled; 1=Dependency_is_enabled
  [2] WKUPDEP_DCAN2_DSP1 rw — Wakeup dependency from DCAN2 module (SWakeup signal) towards DSP1 + L3_MAIN1 + L4PER1 + L4PER2 + L4PER3 domains
    values as the fields of PM_L4PER_MMC3_WKDEP
  [1] WKUPDEP_DCAN2_IPU2 rw — Wakeup dependency from DCAN2 module (SWakeup signal) towards IPU2 + L3_MAIN1 + L4PER1 + L4PER2 + L4PER3 domains
    0=Dependency_is_disabled; 1=Dependency_is_enabled
  [0] WKUPDEP_DCAN2_MPU rw — Wakeup dependency from DCAN2 module (SWakeup signal) towards MPU + L3_MAIN1 + L4PER1 + L4PER2 + L4PER3 domains
    values as the fields of PM_L4PER_MMC3_WKDEP
0x1F4 RM_L4PER2_DCAN2_CONTEXT reset 0x101 — This register contains dedicated DCAN2 context statuses. [warm reset insensitive]
  [8] LOSTMEM_DCAN_BANK rw — Specify if memory-based context in DCAN memory bank has been lost due to a previous power transition or other reset source.
    values as RM_L4PER_GPIO8_CONTEXT.LOSTCONTEXT_RFF
  [0] LOSTCONTEXT_DFF rw — Specify if DFF-based context has been lost due to a previous power transition or other reset source. (set upon assertion of L3INIT_RST signal)
    values as RM_L4PER_GPIO8_CONTEXT.LOSTCONTEXT_RFF
0x1FC RM_L4SEC_SHA2MD52_CONTEXT reset 0x2 — This register contains dedicated SHA2MD52 context statuses. [warm reset insensitive]
  fields as RM_L4PER_GPIO8_CONTEXT
